AUTOSAR XML (schema 4-2-1)
package /ComponentTypes
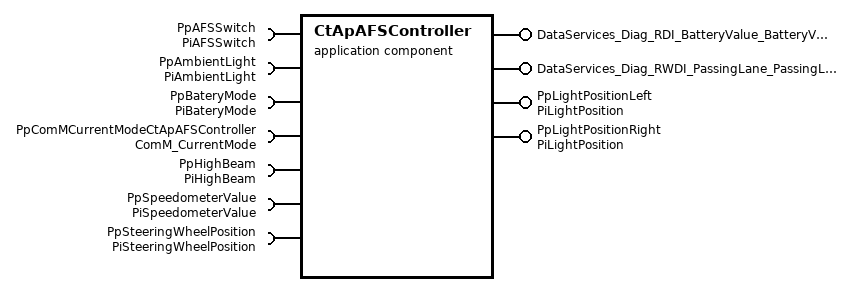
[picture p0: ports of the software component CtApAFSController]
  application sw component type CtApAFSController
    4 x provide port:
      DataServices_Diag_RDI_BatteryValue_BatteryValue: provided-com-specs=[{operation=ConditionCheckRead, queue-length=1}, {operation=ReadData, queue-length=1}], provided-interface=DataServices_Diag_RDI_BatteryValue_BatteryValue
      DataServices_Diag_RWDI_PassingLane_PassingLane_PassingLane: provided-interface=DataServices_Diag_RWDI_PassingLane_PassingLane_PassingLane
        provided-com-specs:
          operation=ConditionCheckRead, queue-length=1
          operation=ReadData, queue-length=1
          operation=WriteData, queue-length=1
      PpLightPositionLeft: provided-com-specs=[{data-element=DeLightLength, init-value=0}, {data-element=DeLightPosition, init-value=0}], provided-interface=PiLightPosition
      PpLightPositionRight: provided-interface=PiLightPosition
        provided-com-specs:
          data-element=DeLightLength, init-value=0
          data-element=DeLightPosition, init-value=constant-reference=CDarkLight
    7 x require port:
      PpAFSSwitch: required-interface=PiAFSSwitch
      PpAmbientLight: nonqueued-receiver-com-spec{data-element=DeAmbientLight, filter=data-filter-type=ALWAYS, init-value=0}, required-interface=PiAmbientLight
      PpBateryMode: nonqueued-receiver-com-spec{data-element=DeBateryMode, filter=data-filter-type=ALWAYS, init-value=1}, required-interface=PiBateryMode
      PpComMCurrentModeCtApAFSController: required-interface=ComM_CurrentMode
      PpHighBeam: required-interface=PiHighBeam
      PpSpeedometerValue: nonqueued-receiver-com-spec{data-element=DeSpeedometerValue, filter=data-filter-type=ALWAYS, init-value=0}, required-interface=PiSpeedometerValue
      PpSteeringWheelPosition: nonqueued-receiver-com-spec{data-element=DeSteeringWheelPosition, filter=data-filter-type=ALWAYS, init-value=0}, required-interface=PiSteeringWheelPosition
    behavior CtApAFSController_InternalBehavior
      5 x operation invoked event:
        OIT_DataServices_Diag_RDI_BatteryValue_BatteryValue_ConditionCheckRead_DataServices_Diag_RDI_BatteryValue_BatteryValue_C3B28864A: start-on-event=DataServices_Diag_RDI_BatteryValue_BatteryValue_ConditionCheckRead, operation=DataServices_Diag_RDI_BatteryValue_BatteryValue.ConditionCheckRead
        OIT_DataServices_Diag_RDI_BatteryValue_BatteryValue_ReadData_DataServices_Diag_RDI_BatteryValue_BatteryValue_ReadData: start-on-event=DataServices_Diag_RDI_BatteryValue_BatteryValue_ReadData, operation=DataServices_Diag_RDI_BatteryValue_BatteryValue.ReadData
        OIT_DataServices_Diag_RWDI_PassingLane_PassingLane_PassingLane_ConditionCheckRead_DataServices_Diag_RWDI_PassingLane_Pas5F15AC2B: start-on-event=DataServices_Diag_RWDI_PassingLane_PassingLane_PassingLane_ConditionCheckRead, operation=DataServices_Diag_RWDI_PassingLane_PassingLane_PassingLane.ConditionCheckRead
        OIT_DataServices_Diag_RWDI_PassingLane_PassingLane_PassingLane_ReadData_DataServices_Diag_RWDI_PassingLane_PassingLane_P8D71540F: start-on-event=DataServices_Diag_RWDI_PassingLane_PassingLane_PassingLane_ReadData, operation=DataServices_Diag_RWDI_PassingLane_PassingLane_PassingLane.ReadData
        OIT_DataServices_Diag_RWDI_PassingLane_PassingLane_PassingLane_WriteData_DataServices_Diag_RWDI_PassingLane_PassingLane_DA0BE9C4: start-on-event=DataServices_Diag_RWDI_PassingLane_PassingLane_PassingLane_WriteData, operation=DataServices_Diag_RWDI_PassingLane_PassingLane_PassingLane.WriteData
      init event CtApAFSController_InitEvent: start-on-event=RCtApAFSController_Init
      4 x data received event, all with start-on-event=RCtApAFSControllerLogic:
        DRT_RCtApAFSControllerLogic_PpAmbientLight_DeAmbientLight: data=PpAmbientLight.DeAmbientLight
        DRT_RCtApAFSControllerLogic_PpBateryMode_DeBateryMode: data=PpBateryMode.DeBateryMode
        DRT_RCtApAFSControllerLogic_PpSpeedometerValue_DeSpeedometerValue: data=PpSpeedometerValue.DeSpeedometerValue
        DRT_RCtApAFSControllerLogic_PpSteeringWheelPosition_DeSteeringWheelPosition: data=PpSteeringWheelPosition.DeSteeringWheelPosition
      7 x runnable:
        DataServices_Diag_RDI_BatteryValue_BatteryValue_ConditionCheckRead
        DataServices_Diag_RDI_BatteryValue_BatteryValue_ReadData
        DataServices_Diag_RWDI_PassingLane_PassingLane_PassingLane_ConditionCheckRead
        DataServices_Diag_RWDI_PassingLane_PassingLane_PassingLane_ReadData
        DataServices_Diag_RWDI_PassingLane_PassingLane_PassingLane_WriteData
        RCtApAFSController_Init
        RCtApAFSControllerLogic: mode-access-point=PpComMCurrentModeCtApAFSController.currentMode
          data-receive-point-by-arguments:
            4 x access:
              REC_PpAmbientLight_DeAmbientLight: accessed-variable=PpAmbientLight.DeAmbientLight
              REC_PpBateryMode_DeBateryMode: accessed-variable=PpBateryMode.DeBateryMode
              REC_PpSpeedometerValue_DeSpeedometerValue: accessed-variable=PpSpeedometerValue.DeSpeedometerValue
              REC_PpSteeringWheelPosition_DeSteeringWheelPosition: accessed-variable=PpSteeringWheelPosition.DeSteeringWheelPosition
          data-send-points:
            4 x access:
              SEND_PpLightPosition_DeLightPosition: accessed-variable=PpLightPositionLeft.DeLightPosition
              SEND_PpLightPositionLeft_DeLightMode: accessed-variable=PpLightPositionLeft.DeLightLength
              SEND_PpLightPositionRight_DeLightMode: accessed-variable=PpLightPositionRight.DeLightLength
              SEND_PpLightPositionRight_DeLightPosition: accessed-variable=PpLightPositionRight.DeLightPosition
          sync call SC_PpAFSSwitch_ReadChannel: operation=PpAFSSwitch.ReadChannel, timeout=0
          sync call SC_PpHighBeam_ReadChannel: operation=PpHighBeam.ReadChannel, timeout=0
  swc implementation CtApAFSController_Implementation: behavior=CtApAFSController_InternalBehavior
    code-descriptors:
      code Default: artifact-descriptors=autosar-engineering-object={short-label=Default, category=SWSRC}
